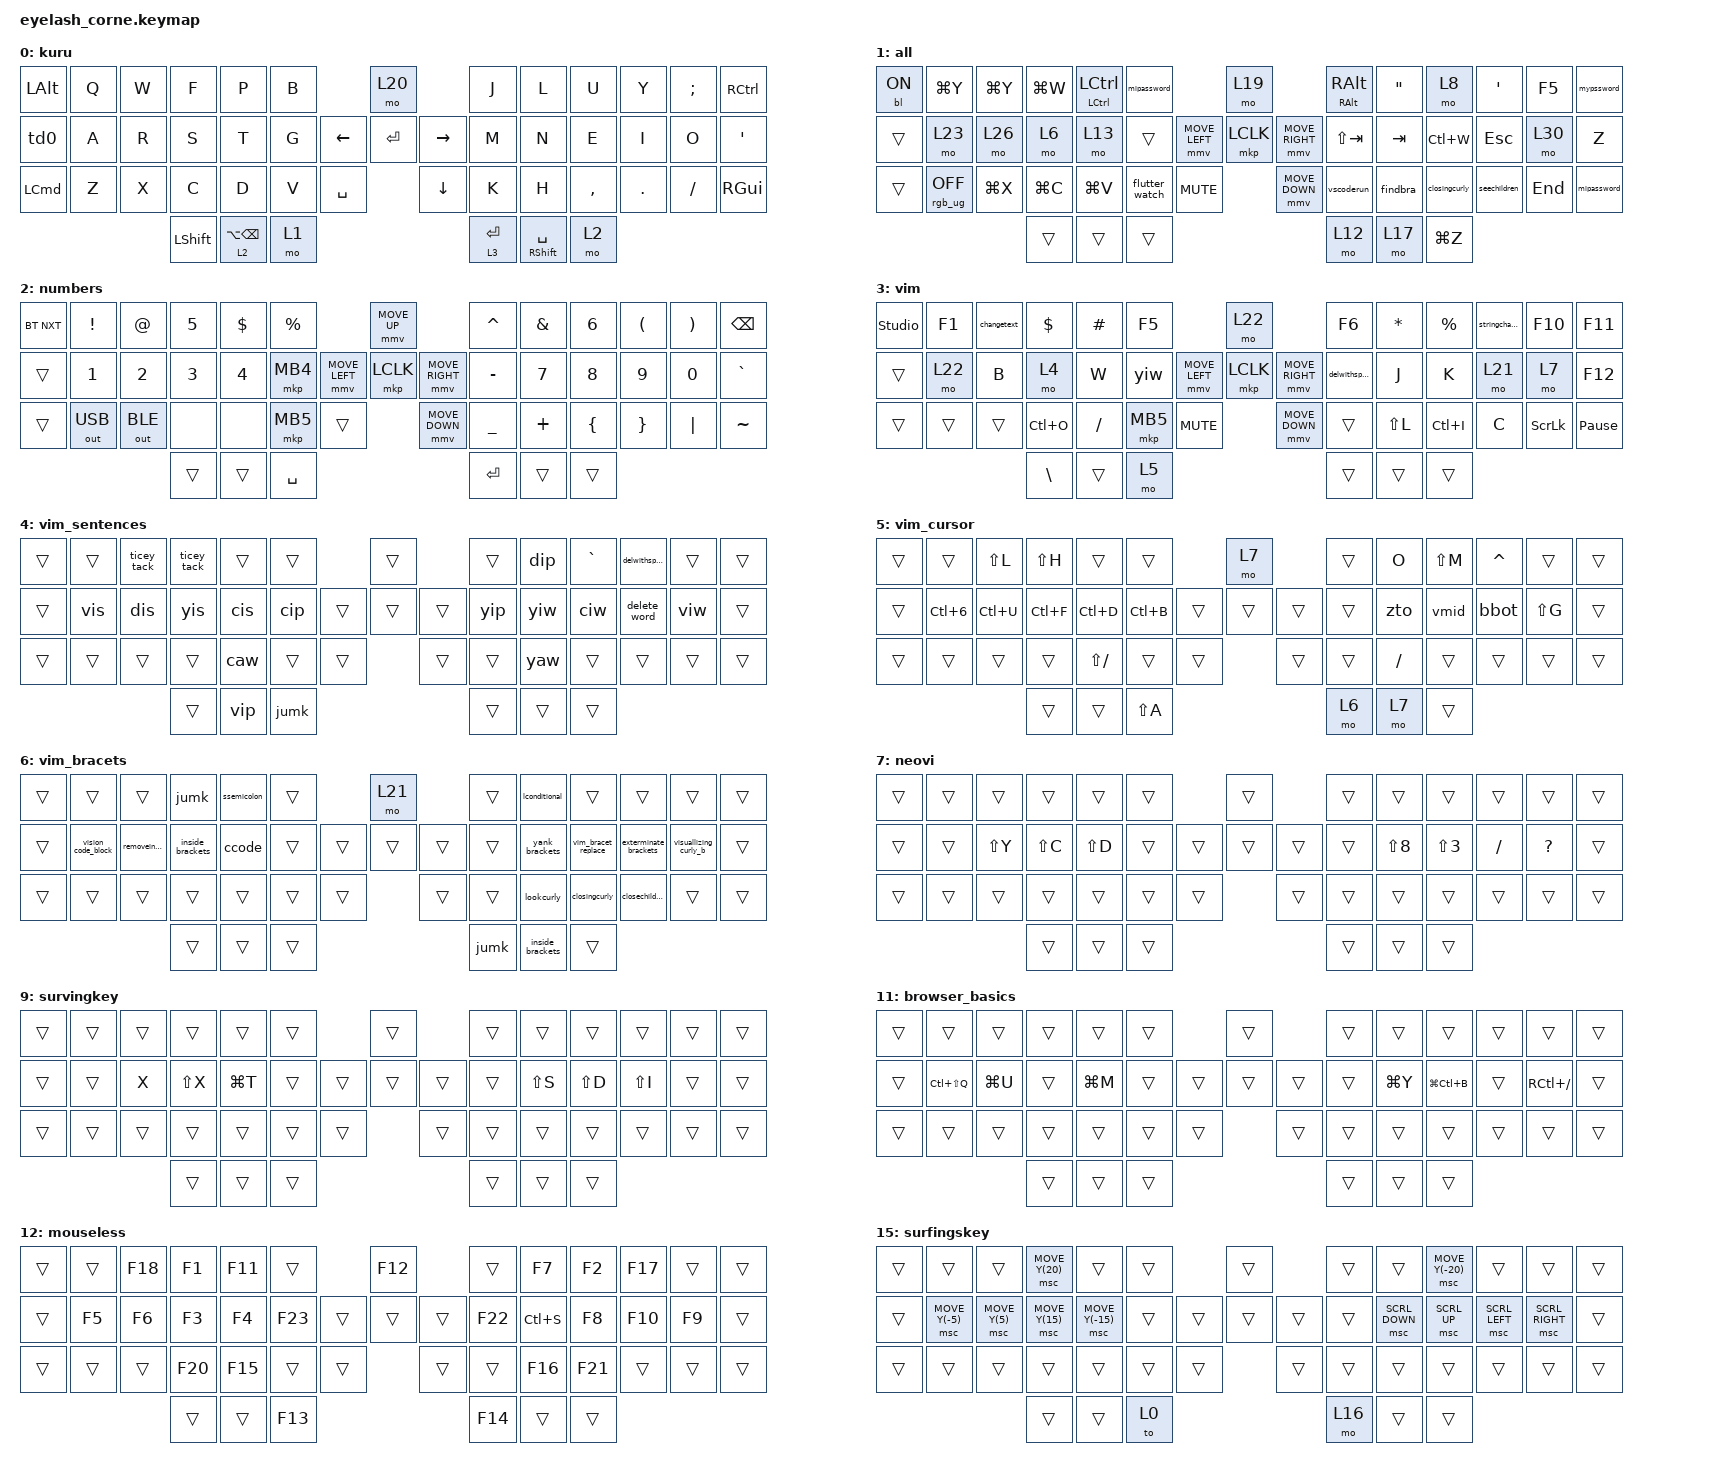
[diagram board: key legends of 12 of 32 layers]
#define ZMK_POINTING_DEFAULT_MOVE_VAL 1200  // 600
#define ZMK_POINTING_DEFAULT_SCRL_VAL 25   // 10

#include <input/processors.dtsi>
#include <zephyr/dt-bindings/input/input-event-codes.h>
#include <behaviors.dtsi>
#include <dt-bindings/zmk/backlight.h>
#include <dt-bindings/zmk/bt.h>
#include <dt-bindings/zmk/keys.h>
#include <dt-bindings/zmk/outputs.h>
#include <dt-bindings/zmk/pointing.h>
#include <dt-bindings/zmk/rgb.h>

&mmv_input_listener { input-processors = <&zip_xy_scaler 2 1>; };

&msc_input_listener { input-processors = <&zip_scroll_scaler 2 1>; };

&msc {
    acceleration-exponent = <1>;      // 0
    time-to-max-speed-ms = <100>;       // 300
    delay-ms = <0>;                   // 0
};

&mmv {
    time-to-max-speed-ms = <500>;
    acceleration-exponent = <1>;
    trigger-period-ms = <16>;
};

&soft_off { hold-time-ms = <2000>; };

/ {
    behaviors {
        td0: td0 {
            compatible = "zmk,behavior-tap-dance";
            display-name = "Shift/Caps Lock Tap Dance";
            #binding-cells = <0>;
            bindings = <&kp LEFT_SHIFT>, <&kp CAPS>;
        };

        new_behavior: new_behavior {
            compatible = "zmk,behavior-hold-tap";
            label = "NEW_BEHAVIOR";
            bindings = <&kp>, <&kp>;

            #binding-cells = <2>;
            flavor = "tap-preferred";
            tapping-term-ms = <230>;
            quick-tap-ms = <230>;
            require-prior-idle-ms = <125>;
        };

        new_behaviorr: new_behaviorr {
            compatible = "zmk,behavior-hold-tap";
            label = "NEW_BEHAVIORR";
            bindings = <&mo>, <&kp>;

            #binding-cells = <2>;
            tapping-term-ms = <230>;
            flavor = "tap-preferred";
            quick-tap-ms = <230>;
            require-prior-idle-ms = <125>;
        };
    };

    rgb_encoder: rgb_encoder {
        compatible = "zmk,behavior-sensor-rotate";
        #sensor-binding-cells = <0>;
        bindings = <&rgb_ug RGB_BRI>, <&rgb_ug RGB_BRD>;
    };

    scroll_encoder: scroll_encoder {
        compatible = "zmk,behavior-sensor-rotate";
        #sensor-binding-cells = <0>;
        bindings = <&msc SCRL_DOWN>, <&msc SCRL_UP>;

        tap-ms = <100>;
    };

    combos {
        compatible = "zmk,combos";

        softoff {
            bindings = <&soft_off>;
            key-positions = <1 15 29>;
        };

        newshitf {
            bindings = <&kp RIGHT_SHIFT>;
            key-positions = <44 46>;
        };
    };

    macros {
        ciw: ciw {
            compatible = "zmk,behavior-macro";
            #binding-cells = <0>;
            bindings = <&kp C &kp I &kp W>;
            label = "CIW";
        };

        viw: viw {
            compatible = "zmk,behavior-macro";
            #binding-cells = <0>;
            bindings = <&kp V &kp I &kp W>;
            label = "VIW";
        };

        yiw: yiw {
            compatible = "zmk,behavior-macro";
            #binding-cells = <0>;
            bindings = <&kp Y &kp I &kp W>;
            label = "YIW";
        };

        ten: ten {
            compatible = "zmk,behavior-macro";
            #binding-cells = <0>;
            bindings = <&kp NUMBER_1 &kp N0>;
            label = "TEN";
        };

        delete_word: delete_word {
            compatible = "zmk,behavior-macro";
            #binding-cells = <0>;
            bindings = <&kp D &kp I &kp W>;
            label = "DELETE_WORD";
        };

        replace_word: visual_w {
            compatible = "zmk,behavior-macro";
            #binding-cells = <0>;
            bindings = <&kp C &kp I &kp LS(W)>;
            label = "VISUAL_W";
        };

        remove_o: remove_o {
            compatible = "zmk,behavior-macro";
            #binding-cells = <0>;
            bindings = <&kp D &kp I &kp LS(W)>;
            label = "REMOVE_O";
        };

        vim_bracet_replace: vim_bracet_replace {
            compatible = "zmk,behavior-macro";
            #binding-cells = <0>;
            bindings = <&kp C &kp I &kp B>;
            label = "VIM_BRACET_REPLACE";
        };

        inside_brackets: inside_brackets {
            compatible = "zmk,behavior-macro";
            #binding-cells = <0>;
            bindings = <&kp C &kp I &kp LS(B)>;
            label = "INSIDE_BRACKETS";
        };

        ccode: erase_in_bracketss {
            compatible = "zmk,behavior-macro";
            #binding-cells = <0>;
            bindings = <&kp Y &kp I &kp B>;
            label = "ERASE_IN_BRACKETSS";
        };

        yank_brackets: yank_brackets {
            compatible = "zmk,behavior-macro";
            #binding-cells = <0>;
            bindings = <&kp Y &kp I &kp LS(B)>;
            label = "YANK_BRACKETS";
        };

        vision_code_block: vision_code_block {
            compatible = "zmk,behavior-macro";
            #binding-cells = <0>;
            bindings = <&kp V &kp I &kp B>;
            label = "VISION_CODE_BLOCK";
        };

        visuallizing_curly_b: visuallizing_curly_brackets {
            compatible = "zmk,behavior-macro";
            #binding-cells = <0>;
            bindings = <&kp V &kp I &kp LS(B)>;
            label = "VISUALLIZING_CURLY_BRACKETS";
        };

        ticey_tack: ticey_tack {
            compatible = "zmk,behavior-macro";
            #binding-cells = <0>;
            bindings = <&kp GRAVE &kp GRAVE>;
            label = "TICEY_TACK";
        };

        zto: zto {
            compatible = "zmk,behavior-macro";
            #binding-cells = <0>;
            bindings = <&kp Z &kp T>;
            label = "ZTO";
        };

        vmid: vmid {
            compatible = "zmk,behavior-macro";
            #binding-cells = <0>;
            bindings = <&kp Z &kp Z>;
            label = "VMID";
        };

        bbot: bbot {
            compatible = "zmk,behavior-macro";
            #binding-cells = <0>;
            bindings = <&kp Z &kp B>;
            label = "BBOT";
        };

        cip: cip {
            compatible = "zmk,behavior-macro";
            #binding-cells = <0>;
            bindings = <&kp C &kp I &kp P>;
            label = "CIP";
        };

        vip: vip {
            compatible = "zmk,behavior-macro";
            #binding-cells = <0>;
            bindings = <&kp V &kp I &kp P>;
            label = "VIP";
        };

        yip: yip {
            compatible = "zmk,behavior-macro";
            #binding-cells = <0>;
            bindings = <&kp Y &kp I &kp P>;
            label = "YIP";
        };

        dip: dip {
            compatible = "zmk,behavior-macro";
            #binding-cells = <0>;
            bindings = <&kp D &kp I &kp P>;
            label = "DIP";
        };

        cis: cis {
            compatible = "zmk,behavior-macro";
            #binding-cells = <0>;
            bindings = <&kp C &kp I &kp S>;
            label = "CIS";
        };

        vis: vis {
            compatible = "zmk,behavior-macro";
            #binding-cells = <0>;
            bindings = <&kp V &kp I &kp S>;
            label = "VIS";
        };

        yis: yis {
            compatible = "zmk,behavior-macro";
            #binding-cells = <0>;
            bindings = <&kp Y &kp I &kp S>;
            label = "YIS";
        };

        dis: dis {
            compatible = "zmk,behavior-macro";
            #binding-cells = <0>;
            bindings = <&kp D &kp I &kp S>;
            label = "DIS";
        };

        caw: caw {
            compatible = "zmk,behavior-macro";
            #binding-cells = <0>;
            bindings = <&kp C &kp A &kp W>;
            label = "CAW";
        };

        yaw: yaw {
            compatible = "zmk,behavior-macro";
            #binding-cells = <0>;
            bindings = <&kp Y &kp A &kp W>;
            label = "YAW";
        };

        endofword: endofword {
            compatible = "zmk,behavior-macro";
            #binding-cells = <0>;
            bindings = <&kp G &kp E>;
            label = "ENDOFWORD";
        };

        jumk: jumk {
            compatible = "zmk,behavior-macro";
            #binding-cells = <0>;
            bindings = <&kp GRAVE &kp N>;
            label = "JUMK";
        };

        splitV: splitV {
            compatible = "zmk,behavior-macro";
            #binding-cells = <0>;
            bindings = <&kp SPACE &kp S &kp V>;
            label = "SPLITV";
        };

        horsplit: horsplit {
            compatible = "zmk,behavior-macro";
            #binding-cells = <0>;
            bindings = <&kp SPACE &kp S &kp H>;
            label = "HORSPLIT";
        };

        closesplit: closesplit {
            compatible = "zmk,behavior-macro";
            #binding-cells = <0>;
            bindings = <&kp SPACE &kp S &kp X>;
            label = "CLOSESPLIT";
        };

        changetext: changetext {
            compatible = "zmk,behavior-macro";
            #binding-cells = <0>;
            bindings = <&kp C &kp I &kp DOUBLE_QUOTES>;
            label = "CHANGETEXT";
        };

        stringchange: stringchange {
            compatible = "zmk,behavior-macro";
            #binding-cells = <0>;
            bindings = <&kp C &kp I &kp SINGLE_QUOTE>;
            label = "STRINGCHANGE";
        };

        fuzzy: fuzzy {
            compatible = "zmk,behavior-macro";
            #binding-cells = <0>;
            bindings = <&kp F &kp Z &kp F>;
            label = "FUZZY";
        };

        aroundpara: aroundpara {
            compatible = "zmk,behavior-macro";
            #binding-cells = <0>;
            bindings = <&kp D &kp A &kp P>;
            label = "AROUNDPARA";
        };

        gospace: gospace {
            compatible = "zmk,behavior-macro";
            #binding-cells = <0>;
            bindings = <&kp F &kp SPACE>;
            label = "GOSPACE";
        };

        findbra: findbra {
            compatible = "zmk,behavior-macro";
            #binding-cells = <0>;
            bindings = <&kp F &kp LS(NUMBER_9)>;
            label = "FINDBRA";
        };

        lookcurly: lookcurly {
            compatible = "zmk,behavior-macro";
            #binding-cells = <0>;
            bindings = <&kp F &kp LEFT_BRACE>;
            label = "LOOKCURLY";
        };

        ssemicolon: ssemicolon {
            compatible = "zmk,behavior-macro";
            #binding-cells = <0>;
            bindings = <&kp F &kp SEMICOLON>;
            label = "SSEMICOLON";
        };

        closingcurly: closingcurly {
            compatible = "zmk,behavior-macro";
            #binding-cells = <0>;
            bindings = <&kp F &kp LS(N0)>;
            label = "CLOSINGCURLY";
        };

        lockedbra: lockedbra {
            compatible = "zmk,behavior-macro";
            #binding-cells = <0>;
            bindings = <&kp F &kp RIGHT_BRACE>;
            label = "LOCKEDBRA";
        };

        seechildren: seechildren {
            compatible = "zmk,behavior-macro";
            #binding-cells = <0>;
            bindings = <&kp F &kp LEFT_BRACKET>;
            label = "SEECHILDREN";
        };

        closechildren: closechildren {
            compatible = "zmk,behavior-macro";
            #binding-cells = <0>;
            bindings = <&kp F &kp RIGHT_BRACKET>;
            label = "CLOSECHILDREN";
        };

        lconditional: lconditional {
            compatible = "zmk,behavior-macro";
            #binding-cells = <0>;
            bindings = <&kp F &kp LS(SEMI)>;
            label = "LCONDITIONAL";
        };

        mask: mask {
            compatible = "zmk,behavior-macro";
            #binding-cells = <0>;
            bindings = <&kp CARET &kp LS(M)>;
            label = "MASK";
        };

        Component: Component {
            compatible = "zmk,behavior-macro";
            #binding-cells = <0>;
            bindings = <&kp CARET &kp LA(LG(K))>;
            label = "COMPONENT";
        };

        mipassword: mipassword {
            compatible = "zmk,behavior-macro";
            #binding-cells = <0>;
            bindings = <&kp M &kp I &kp G &kp B &kp Y &kp T &kp E &kp DOLLAR &kp PERCENT>;
            label = "MIPASSWORD";
        };

        muxprev: muxprev {
            compatible = "zmk,behavior-macro";
            #binding-cells = <0>;
            bindings = <&kp LC(N) &kp LC(P)>;
            label = "MUXPREV";
        };

        delwithspacedaw: delwithspacedaw {
            compatible = "zmk,behavior-macro";
            #binding-cells = <0>;
            bindings = <&kp D &kp W>;
            label = "DELWITHSPACEDAW";
        };

        winsert: winsert {
            compatible = "zmk,behavior-macro";
            #binding-cells = <0>;
            bindings = <&kp LC(O) &kp W>;
            label = "WINSERT";
        };

        begininsertmode: begininsertmode {
            compatible = "zmk,behavior-macro";
            #binding-cells = <0>;
            bindings = <&kp LC(O) &kp B>;
            label = "BEGININSERTMODE";
        };

        endinertm: endinertm {
            compatible = "zmk,behavior-macro";
            #binding-cells = <0>;
            bindings = <&kp LC(O) &kp RIGHT_ARROW &kp E>;
            label = "ENDINERTM";
        };

        var: var {
            compatible = "zmk,behavior-macro";
            #binding-cells = <0>;
            bindings = <&kp DOLLAR &kp V &kp A &kp R>;
            label = "VAR";
        };

        eloquentchain: eloquentchain {
            compatible = "zmk,behavior-macro";
            #binding-cells = <0>;
            bindings = <&kp MINUS &kp GREATER_THAN>;
            label = "ELOQUENTCHAIN";
        };

        phpopening: phpopening {
            compatible = "zmk,behavior-macro";
            #binding-cells = <0>;
            bindings = <&kp LESS_THAN &kp QUESTION &kp P &kp H &kp P &kp QUESTION &kp GREATER_THAN>;
            label = "PHPOPENING";
        };

        mypssword: mypssword {
            compatible = "zmk,behavior-macro";
            #binding-cells = <0>;
            bindings = <&kp SINGLE_QUOTE &kp PERIOD>;
            label = "MYPSSWORD";
        };

        lastinertlo: lastinertlo {
            compatible = "zmk,behavior-macro";
            #binding-cells = <0>;
            bindings = <&kp SINGLE_QUOTE &kp CARET>;
            label = "LASTINERTLO";
        };

        lastvimchange: lastvimchange {
            compatible = "zmk,behavior-macro";
            #binding-cells = <0>;
            bindings = <&kp SINGLE_QUOTE &kp LEFT_BRACKET>;
            label = "LASTVIMCHANGE";
        };

        firstvimchange: firstvimchange {
            compatible = "zmk,behavior-macro";
            #binding-cells = <0>;
            bindings = <&kp SINGLE_QUOTE &kp RIGHT_BRACKET>;
            label = "FIRSTVIMCHANGE";
        };

        nexterror: nexterror {
            compatible = "zmk,behavior-macro";
            #binding-cells = <0>;
            bindings = <&kp RIGHT_BRACKET &kp E>;
            label = "NEXTERROR";
        };

        nextdiagnostic: nextdiagnostic {
            compatible = "zmk,behavior-macro";
            #binding-cells = <0>;
            bindings = <&kp RIGHT_BRACKET &kp D>;
            label = "NEXTDIAGNOSTIC";
        };

        previousdiagnostic: previousdiagnostic {
            compatible = "zmk,behavior-macro";
            #binding-cells = <0>;
            bindings = <&kp LEFT_BRACKET &kp D>;
            label = "PREVIOUSDIAGNOSTIC";
        };

        previouserror: previouserror {
            compatible = "zmk,behavior-macro";
            #binding-cells = <0>;
            bindings = <&kp LEFT_BRACKET &kp E>;
            label = "PREVIOUSERROR";
        };

        removeinsidebraa: removeinsidebraa {
            compatible = "zmk,behavior-macro";
            #binding-cells = <0>;
            bindings = <&kp D &kp I &kp B>;
            label = "REMOVEINSIDEBRAA";
        };

        vision_curly_brackets: vision_curly_brackets {
            compatible = "zmk,behavior-macro";
            #binding-cells = <0>;
            bindings = <&kp V &kp I &kp LS(B)>;
            label = "VISION_CURLY_BRACKETS";
        };

        exterminate_brackets: exterminate_brackets {
            compatible = "zmk,behavior-macro";
            #binding-cells = <0>;
            bindings = <&kp D &kp I &kp LS(B)>;
            label = "EXTERMINATE_BRACKETS";
        };

        vscoderun: vscoderun {
            compatible = "zmk,behavior-macro";
            #binding-cells = <0>;
            bindings = <&kp CARET &kp F5>;
            label = "VSCODERUN";
        };

        flutter_watch: flutter_watch {
            compatible = "zmk,behavior-macro";
            #binding-cells = <0>;
            bindings = <&none &kp F &kp L &kp U &kp T &kp T &kp E &kp R &kp MINUS &kp W &kp A &kp T &kp C &kp H>;
            label = "FLUTTER_WATCH";
        };

        browser_surfing: browser_surfing {
            compatible = "zmk,behavior-macro";
            #binding-cells = <0>;
            bindings = <&none &kp H &kp T &kp T &kp P &kp S &kp COLON &kp FSLH &kp FSLH &kp D &kp R &kp I &kp V &kp E &kp DOT &kp G &kp O &kp O &kp G &kp L &kp E &kp DOT &kp C &kp O &kp M &kp FSLH &kp F &kp I &kp L &kp E &kp FSLH &kp D &kp FSLH &kp N1 &kp LS(Y) &kp T &kp LS(Q) &kp MINUS &kp LS(N) &kp E &kp U &kp T &kp M &kp T &kp LS(R) &kp O &kp N &kp N &kp H &kp G &kp LS(S) &kp B &kp LS(K) &kp N5 &kp LS(H) &kp LS(E) &kp UNDER &kp N0 &kp G &kp Y &kp X &kp LS(Z) &kp T &kp O &kp LS(G) &kp LS(U) &kp FSLH &kp V &kp I &kp E &kp W &kp QMARK &kp U &kp S &kp P &kp EQUAL &kp S &kp H &kp A &kp R &kp I &kp N &kp G>;
            label = "BROWSER_SURFING";
        };
    };

    keymap {
        compatible = "zmk,keymap";

        default_layer {
            display-name = "kuru";
            bindings = <
&kp LEFT_ALT      &kp Q  &kp W  &kp F           &kp P                           &kp B                         &mo 20                &kp J        &kp L                            &kp U      &kp Y    &kp SEMICOLON  &kp RIGHT_CONTROL
&td0              &kp A  &kp R  &kp S           &kp T                           &kp G               &kp LEFT  &kp ENTER  &kp RIGHT  &kp M        &kp N                            &kp E      &kp I    &kp O          &kp SQT
&kp LEFT_COMMAND  &kp Z  &kp X  &kp C           &kp D                           &kp V  &kp SPACE              &kp DOWN              &kp K        &kp H                            &kp COMMA  &kp DOT  &kp FSLH       &kp RIGHT_GUI
                                &kp LEFT_SHIFT  &new_behaviorr 2 LA(BACKSPACE)  &mo 1                                               &lt 3 ENTER  &new_behavior RIGHT_SHIFT SPACE  &mo 2
            >;

            sensor-bindings = <&inc_dec_kp C_VOLUME_UP C_VOLUME_DOWN>;
        };

        all_layer {
            display-name = "all";
            bindings = <
&bl BL_ON  &kp LG(Y)        &kp LG(Y)  &kp LG(W)  &mt LCTRL LCTRL  &mipassword                                   &mo 19                           &mt RIGHT_ALT RIGHT_ALT  &kp DOUBLE_QUOTES  &mo 8          &kp SINGLE_QUOTE  &kp F5   &mypssword
&trans     &mo 23           &mo 26     &mo 6      &mo 13           &trans                        &mmv MOVE_LEFT  &mkp LCLK       &mmv MOVE_RIGHT  &kp LS(TAB)              &kp TAB            &kp LC(W)      &kp ESCAPE        &mo 30   &kp Z
&trans     &rgb_ug RGB_OFF  &kp LG(X)  &kp LG(C)  &kp LG(V)        &flutter_watch  &kp C_MUTE                    &mmv MOVE_DOWN                   &vscoderun               &findbra           &closingcurly  &seechildren      &kp END  &mipassword
                                       &trans     &trans           &trans                                                                         &mo 12                   &mo 17             &kp LG(Z)
            >;

            sensor-bindings = <&scroll_encoder>;
        };

        numbers_layer {
            display-name = "numbers";
            bindings = <
&bt BT_NXT  &kp EXCL      &kp AT        &kp N5        &kp DLLR      &kp PRCNT                            &mmv MOVE_UP                     &kp CARET  &kp AMPS  &kp NUMBER_6  &kp LPAR  &kp RPAR  &kp BSPC
&trans      &kp NUMBER_1  &kp NUMBER_2  &kp NUMBER_3  &kp NUMBER_4  &mkp MB4             &mmv MOVE_LEFT  &mkp LCLK       &mmv MOVE_RIGHT  &kp MINUS  &kp N7    &kp N8        &kp N9    &kp N0    &kp GRAVE
&trans      &out OUT_USB  &out OUT_BLE  &none         &none         &mkp MB5   &trans                    &mmv MOVE_DOWN                   &kp UNDER  &kp PLUS  &kp LBRC      &kp RBRC  &kp PIPE  &kp TILDE
                                        &trans        &trans        &kp SPACE                                                             &kp RET    &trans    &trans
            >;

            sensor-bindings = <&scroll_encoder>;
        };

        vim_layer {
            display-name = "vim";
            bindings = <
&studio_unlock  &kp F1  &changetext  &kp DOLLAR     &kp HASH   &kp F5                                  &mo 22                           &kp F6            &kp ASTERISK  &kp PERCENT  &stringchange  &kp F10         &kp F11
&trans          &mo 22  &kp B        &mo 4          &kp W      &yiw                    &mmv MOVE_LEFT  &mkp LCLK       &mmv MOVE_RIGHT  &delwithspacedaw  &kp J         &kp K        &mo 21         &mo 7           &kp F12
&trans          &trans  &trans       &kp LC(O)      &kp SLASH  &mkp MB5  &kp C_MUTE                    &mmv MOVE_DOWN                   &trans            &kp LS(L)     &kp LC(I)    &kp C          &kp SCROLLLOCK  &kp PAUSE_BREAK
                                     &kp BACKSLASH  &trans     &mo 5                                                                    &trans            &trans        &trans
            >;

            sensor-bindings = <&scroll_encoder>;
        };

        vim_sentences {
            bindings = <
&trans  &trans  &ticey_tack  &ticey_tack  &trans  &trans                    &trans          &trans  &dip    &kp GRAVE  &delwithspacedaw  &trans  &trans
&trans  &vis    &dis         &yis         &cis    &cip              &trans  &trans  &trans  &yip    &yiw    &ciw       &delete_word      &viw    &trans
&trans  &trans  &trans       &trans       &caw    &trans  &trans            &trans          &trans  &yaw    &trans     &trans            &trans  &trans
                             &trans       &vip    &jumk                                     &trans  &trans  &trans
            >;
        };

        vim_cursor {
            bindings = <
&trans  &trans            &kp LS(L)  &kp LS(H)  &trans         &trans                       &mo 7           &trans  &kp O      &kp LS(M)  &kp CARET  &trans     &trans
&trans  &kp LC(NUMBER_6)  &kp LC(U)  &kp LC(F)  &kp LC(D)      &kp LC(B)            &trans  &trans  &trans  &trans  &zto       &vmid      &bbot      &kp LS(G)  &trans
&trans  &trans            &trans     &trans     &kp LS(SLASH)  &trans     &trans            &trans          &trans  &kp SLASH  &trans     &trans     &trans     &trans
                                     &trans     &trans         &kp LS(A)                                    &mo 6   &mo 7      &trans
            >;
        };

        vim_bracets {
            bindings = <
&trans  &trans              &trans             &jumk             &ssemicolon  &trans                    &mo 21          &trans  &lconditional     &trans               &trans                 &trans                 &trans
&trans  &vision_code_block  &removeinsidebraa  &inside_brackets  &ccode       &trans            &trans  &trans  &trans  &trans  &yank_brackets    &vim_bracet_replace  &exterminate_brackets  &visuallizing_curly_b  &trans
&trans  &trans              &trans             &trans            &trans       &trans  &trans            &trans          &trans  &lookcurly        &closingcurly        &closechildren         &trans                 &trans
                                               &trans            &trans       &trans                                    &jumk   &inside_brackets  &trans
            >;
        };

        neovi {
            bindings = <
&trans  &trans  &trans     &trans     &trans     &trans                    &trans          &trans  &trans      &trans            &trans     &trans     &trans
&trans  &trans  &kp LS(Y)  &kp LS(C)  &kp LS(D)  &trans            &trans  &trans  &trans  &trans  &kp LS(N8)  &kp LS(NUMBER_3)  &kp SLASH  &kp QMARK  &trans
&trans  &trans  &trans     &trans     &trans     &trans  &trans            &trans          &trans  &trans      &trans            &trans     &trans     &trans
                           &trans     &trans     &trans                                    &trans  &trans      &trans
            >;
        };

        browser {
            bindings = <
&trans  &trans             &trans  &kp LG(W)          &trans             &trans                               &mo 12          &trans  &trans  &trans  &kp LG(T)  &trans  &trans
&trans  &kp LC(LA(LS(F)))  &trans  &kp LC(LA(LS(B)))  &kp LC(LA(LS(P)))  &kp LS(LA(LC(W)))            &trans  &trans  &trans  &trans  &mo 15  &trans  &mo 16     &mo 11  &trans
&trans  &trans             &trans  &trans             &trans             &trans             &trans            &trans          &trans  &trans  &trans  &trans     &trans  &trans
                                   &trans             &trans             &trans                                               &mo 9   &trans  &trans
            >;
        };

        survingkey {
            bindings = <
&trans  &trans  &trans  &trans     &trans     &trans                    &trans          &trans  &trans     &trans     &trans     &trans  &trans
&trans  &trans  &kp X   &kp LS(X)  &kp LG(T)  &trans            &trans  &trans  &trans  &trans  &kp LS(S)  &kp LS(D)  &kp LS(I)  &trans  &trans
&trans  &trans  &trans  &trans     &trans     &trans  &trans            &trans          &trans  &trans     &trans     &trans     &trans  &trans
                        &trans     &trans     &trans                                    &trans  &trans     &trans
            >;
        };

        browser_shortcuts {
            bindings = <
&trans  &trans  &trans  &trans         &trans        &trans                    &trans          &trans  &trans         &trans     &trans                 &trans                         &trans
&trans  &trans  &trans  &kp LG(MINUS)  &kp LG(PLUS)  &trans            &trans  &trans  &trans  &trans  &kp LG(LS(P))  &kp LC(P)  &kp LC(LG(LA(LS(X))))  &kp LG(LC(LA(LS(SEMICOLON))))  &trans
&trans  &trans  &trans  &trans         &trans        &trans  &trans            &trans          &trans  &trans         &trans     &trans                 &trans                         &trans
                        &trans         &trans        &trans                                    &trans  &trans         &trans
            >;
        };

        browser_basics {
            bindings = <
&trans  &trans         &trans     &trans  &trans     &trans                    &trans          &trans  &trans     &trans         &trans  &trans         &trans
&trans  &kp LC(LS(Q))  &kp LG(U)  &trans  &kp LG(M)  &trans            &trans  &trans  &trans  &trans  &kp LG(Y)  &kp LG(LC(B))  &trans  &kp RC(SLASH)  &trans
&trans  &trans         &trans     &trans  &trans     &trans  &trans            &trans          &trans  &trans     &trans         &trans  &trans         &trans
                                  &trans  &trans     &trans                                    &trans  &trans     &trans
            >;
        };

        mouseless {
            bindings = <
&trans  &trans  &kp F18  &kp F1   &kp F11  &trans                     &kp F12          &trans   &kp F7     &kp F2   &kp F17  &trans  &trans
&trans  &kp F5  &kp F6   &kp F3   &kp F4   &kp F23            &trans  &trans   &trans  &kp F22  &kp LC(S)  &kp F8   &kp F10  &kp F9  &trans
&trans  &trans  &trans   &kp F20  &kp F15  &trans   &trans            &trans           &trans   &kp F16    &kp F21  &trans   &trans  &trans
                         &trans   &trans   &kp F13                                     &kp F14  &trans     &trans
            >;
        };

        raycast {
            bindings = <
&trans  &trans              &kp LS(LG(PERIOD))  &kp LS(LA(LC(G)))  &trans  &trans                    &mo 15          &kp LS(LG(C))          &kp LG(Y)          &kp LS(LA(LG(PERIOD)))  &kp LG(PERIOD)         &trans                 &trans
&trans  &kp LG(LS(PERIOD))  &mo 14              &mo 17             &trans  &trans            &trans  &trans  &trans  &kp LG(LA(LC(LS(Y))))  &kp LS(LC(COMMA))  &kp LG(LA(LC(LS(U))))   &kp LG(LA(LC(LS(I))))  &kp LC(LA(LS(X)))      &trans
&trans  &trans              &kp LC(X)           &kp LS(LG(R))      &trans  &trans  &trans            &trans          &kp LG(I)              &kp LG(K)          &kp LG(O)               &kp LG(ENTER)          &kp LS(LC(LA(SLASH)))  &trans
                                                &trans             &trans  &mo 19                                    &kp LS(LA(Y))          &kp LS(LG(L))      &kp LC(LS(Q))
            >;
        };

        raycast_apps {
            bindings = <
&trans  &trans  &trans  &kp LS(LG(Z))  &trans  &trans                    &trans          &trans         &trans             &kp LG(LA(LC(LS(D))))  &trans                 &trans                 &trans
&trans  &trans  &trans  &trans         &trans  &trans            &trans  &trans  &trans  &trans         &kp LA(LS(LG(G)))  &kp LG(K)              &kp LG(LC(LA(LS(L))))  &kp LG(LC(LA(LS(K))))  &trans
&trans  &trans  &trans  &trans         &trans  &trans  &trans            &trans          &trans         &trans             &trans                 &trans                 &trans                 &trans
                        &trans         &trans  &mo 15                                    &kp LC(LS(Q))  &trans             &trans
            >;
        };

        surfingskey {
            bindings = <
&trans  &trans           &trans          &msc MOVE_Y(20)  &trans            &trans                    &trans          &trans  &trans          &msc MOVE_Y(-20)  &trans          &trans           &trans
&trans  &msc MOVE_Y(-5)  &msc MOVE_Y(5)  &msc MOVE_Y(15)  &msc MOVE_Y(-15)  &trans            &trans  &trans  &trans  &trans  &msc SCRL_DOWN  &msc SCRL_UP      &msc SCRL_LEFT  &msc SCRL_RIGHT  &trans
&trans  &trans           &trans          &trans           &trans            &trans  &trans            &trans          &trans  &trans          &trans            &trans          &trans           &trans
                                         &trans           &trans            &to 0                                     &mo 16  &trans          &trans
            >;
        };

        surf {
            bindings = <
&trans  &trans  &trans  &trans     &trans     &trans                    &trans          &trans  &trans          &none         &trans          &trans           &trans
&trans  &trans  &trans  &mkp LCLK  &mkp RCLK  &trans            &trans  &trans  &trans  &trans  &mmv MOVE_DOWN  &mmv MOVE_UP  &mmv MOVE_LEFT  &mmv MOVE_RIGHT  &trans
&trans  &trans  &trans  &trans     &trans     &trans  &trans            &trans          &trans  &trans          &trans        &trans          &trans           &trans
                        &trans     &trans     &to 0                                     &to 15  &trans          &trans
            >;
        };

        tmux_ghostty {
            bindings = <
&trans  &trans           &trans          &trans        &trans        &trans                    &trans          &trans  &trans         &kp LS(A)  &trans                 &trans                    &trans
&trans  &firstvimchange  &lastvimchange  &lastinertlo  &lastinertlo  &trans            &trans  &trans  &trans  &trans  &kp LC(LS(R))  &kp LC(N)  &kp LS(LA(LC(LG(Z))))  &kp LG(LA(LC(LS(SEMI))))  &trans
&trans  &trans           &trans          &trans        &trans        &trans  &trans            &trans          &trans  &trans         &trans     &trans                 &trans                    &trans
                                         &trans        &trans        &trans                                    &trans  &trans         &trans
            >;
        };

        figma {
            bindings = <
&trans  &trans         &mt LS(LG(C)) LG(LS(V))  &mt LA(LG(C)) LG(C)  &mt LA(LG(V)) LG(V)  &trans                         &trans          &trans  &trans  &trans  &trans  &trans  &trans
&to 0   &kp BACKSPACE  &kp LG(Z)                &kp LEFT_SHIFT       &mt LS(LA(A)) LS(A)  &mt I LS(X)            &trans  &trans  &trans  &trans  &trans  &trans  &trans  &trans  &trans
&trans  &trans         &trans                   &mt LS(SPACE) RG(K)  &mt K V              &trans       &trans            &trans          &trans  &trans  &trans  &trans  &trans  &trans
                                                &trans               &mo 20               &mo 19                                         &trans  &trans  &trans
            >;
        };

        symbols_layer {
            bindings = <
&rgb_ug RGB_ON  &trans     &rgb_ug RGB_COLOR_HSB(0,100,45)    &kp UNDER   &rgb_ug RGB_EFF                   &trans                    &trans          &trans  &rgb_ug RGB_EFR  &kp MINUS  &rgb_ug RGB_COLOR_HSB(124,100,48)  &trans         &rgb_ug RGB_OFF
&trans          &kp CARET  &kp SLASH                          &kp DOLLAR  &kp PERCENT                       &trans            &trans  &trans  &trans  &trans  &kp HASH         &kp AT     &kp DOLLAR                         &kp BACKSLASH  &trans
&trans          &trans     &rgb_ug RGB_COLOR_HSB(221,100,50)  &trans      &rgb_ug RGB_COLOR_HSB(66,100,49)  &trans  &trans            &trans          &trans  &trans           &trans     &rgb_ug RGB_COLOR_HSB(41,100,49)   &trans         &trans
                                                              &trans      &trans                            &trans                                    &trans  &trans           &trans
            >;
        };

        captl {
            bindings = <
&trans     &kp LS(Q)  &kp LS(W)  &kp LS(F)  &kp LS(P)  &kp LS(B)                    &trans          &kp LS(J)  &kp LS(L)  &kp LS(U)      &kp LS(Y)       &kp LS(SEMICOLON)  &trans
&kp LS(Q)  &kp LS(A)  &kp LS(R)  &kp LS(S)  &kp LS(T)  &kp LS(G)            &trans  &trans  &trans  &kp LS(M)  &kp LS(N)  &kp LS(E)      &kp LS(I)       &kp LS(O)          &kp LS(Z)
&trans     &kp LS(Z)  &kp LS(X)  &kp LS(C)  &kp LS(D)  &kp LS(V)  &trans            &trans          &kp LS(K)  &kp LS(H)  &kp LS(COMMA)  &kp LS(PERIOD)  &kp LS(SLASH)      &trans
                                 &trans     &kp LS(Q)  &mo 19                                       &trans     &trans     &trans
            >;
        };

        vimuium {
            bindings = <
&trans  &trans               &trans           &kp Q           &trans             &trans                      &trans          &trans     &trans     &kp LS(NUMBER_2)  &trans       &trans  &trans
&trans  &previousdiagnostic  &nextdiagnostic  &previouserror  &nexterror         &trans              &trans  &trans  &trans  &trans     &kp LC(N)  &kp LC(P)         &aroundpara  &fuzzy  &trans
&trans  &trans               &trans           &trans          &trans             &trans    &trans            &trans          &trans     &trans     &trans            &trans       &trans  &trans
                                              &trans          &kp LG(BACKSPACE)  &muxprev                                    &kp LC(O)  &trans     &trans
            >;
        };

        fucs {
            bindings = <
&trans  &trans  &trans       &trans   &trans     &trans                    &trans          &trans  &trans     &trans     &trans     &trans     &trans
&trans  &trans  &closesplit  &splitV  &horsplit  &trans            &trans  &trans  &trans  &trans  &kp LC(H)  &kp LC(L)  &kp LC(J)  &kp LC(K)  &trans
&trans  &trans  &trans       &trans   &trans     &trans  &trans            &trans          &trans  &trans     &trans     &trans     &trans     &trans
                             &trans   &trans     &trans                                    &trans  &trans     &trans
            >;
        };

        workspaces {
            bindings = <
&trans  &trans  &trans         &kp LG(LA(LS(W)))  &trans             &trans                    &trans          &trans  &trans             &kp LG(LA(LS(U)))  &trans             &trans             &trans
&trans  &trans  &kp LA(LG(E))  &mo 24             &kp LG(LA(LS(B)))  &trans            &trans  &trans  &trans  &trans  &kp LG(LA(LS(S)))  &kp LG(LA(LS(D)))  &kp LG(LA(LS(F)))  &kp LG(LA(LS(G)))  &trans
&trans  &trans  &trans         &trans             &kp LG(LA(LS(Y)))  &trans  &trans            &trans          &trans  &kp LG(LA(LS(A)))  &trans             &trans             &trans             &trans
                               &trans             &trans             &trans                                    &mo 25  &trans             &trans
            >;
        };

        workspace_layouts {
            bindings = <
&trans  &trans         &trans  &trans  &trans             &trans                    &kp LG(LS(MINUS))          &trans             &trans             &trans         &trans         &trans         &trans
&trans  &kp LG(SLASH)  &trans  &trans  &kp LG(PERIOD)     &trans            &trans  &trans             &trans  &trans             &kp LG(LS(H))      &kp LG(LS(J))  &kp LG(LS(K))  &kp LG(LS(L))  &trans
&trans  &trans         &trans  &trans  &kp LG(LS(MINUS))  &trans  &trans            &trans                     &trans             &kp LG(LS(EQUAL))  &trans         &trans         &trans         &trans
                               &trans  &trans             &trans                                               &kp LG(LS(EQUAL))  &trans             &trans
            >;
        };

        wordspace_focus {
            bindings = <
&trans  &trans     &trans  &kp LG(LS(MINUS))  &trans          &trans                    &trans          &trans  &trans         &kp LG(LS(EQUAL))  &trans     &trans     &trans
&trans  &kp LG(B)  &trans  &trans             &kp LG(LS(A))   &trans            &trans  &trans  &trans  &trans  &kp LG(H)      &kp LG(L)          &kp LG(J)  &kp LG(K)  &trans
&trans  &trans     &trans  &trans             &kp LG(PERIOD)  &trans  &trans            &trans          &trans  &kp LG(SLASH)  &trans             &trans     &trans     &trans
                           &trans             &trans          &trans                                    &trans  &trans         &trans
            >;
        };

        arrow_movements {
            bindings = <
&trans  &trans  &trans  &trans  &trans  &trans                     &kp LS(A)          &trans  &trans    &trans        &trans          &trans     &trans
&trans  &mo 28  &trans  &mo 27  &mo 29  &trans             &trans  &trans     &trans  &trans  &kp DOWN  &kp UP_ARROW  &kp LEFT_ARROW  &kp RIGHT  &trans
&trans  &trans  &trans  &trans  &trans  &trans   &trans            &trans             &trans  &trans    &trans        &trans          &trans     &trans
                        &trans  &trans  &tog 16                                       &trans  &trans    &trans
            >;
        };

        best_move {
            bindings = <
&trans  &trans  &trans  &trans  &trans  &trans                    &trans          &trans  &trans              &trans               &trans        &trans            &trans
&trans  &trans  &trans  &trans  &trans  &trans            &trans  &trans  &trans  &trans  &kp LA(LEFT_ARROW)  &kp LA(RIGHT_ARROW)  &kp LA(DOWN)  &kp LA(UP_ARROW)  &trans
&trans  &trans  &trans  &trans  &trans  &trans  &trans            &trans          &trans  &trans              &trans               &trans        &trans            &trans
                        &trans  &trans  &trans                                    &trans  &trans              &trans
            >;
        };

        gar {
            bindings = <
&trans  &trans  &trans  &trans  &trans  &trans                    &trans          &trans  &trans              &trans               &trans              &trans            &trans
&trans  &trans  &trans  &trans  &trans  &trans            &trans  &trans  &trans  &trans  &kp LG(LEFT_ARROW)  &kp LG(RIGHT_ARROW)  &kp LG(DOWN_ARROW)  &kp LG(UP_ARROW)  &trans
&trans  &trans  &trans  &trans  &trans  &trans  &trans            &trans          &trans  &trans              &trans               &trans              &trans            &trans
                        &trans  &trans  &trans                                    &trans  &trans              &trans
            >;
        };

        layer_29 {
            bindings = <
&trans  &trans  &trans  &trans  &trans  &trans                    &trans          &trans  &trans            &trans    &trans      &trans     &trans
&trans  &trans  &trans  &trans  &trans  &trans            &trans  &trans  &trans  &trans  &begininsertmode  &winsert  &endinertm  &kp LC(O)  &trans
&trans  &trans  &trans  &trans  &trans  &trans  &trans            &trans          &trans  &trans            &trans    &trans      &trans     &trans
                        &trans  &trans  &trans                                    &trans  &trans            &trans
            >;
        };

        coding {
            bindings = <
&bt BT_SEL 2    &trans            &trans             &kp UNDER       &trans             &trans                    &trans          &trans  &trans                &kp MINUS              &trans         &trans  &bt BT_SEL 4
&trans          &kp LEFT_BRACKET  &kp RIGHT_BRACKET  &kp LEFT_BRACE  &kp RIGHT_BRACE    &trans            &trans  &trans  &trans  &trans  &kp LEFT_PARENTHESIS  &kp RIGHT_PARENTHESIS  &kp SEMICOLON  &trans  &trans
&bt BT_CLR_ALL  &trans            &trans             &trans          &kp LS(SEMICOLON)  &trans  &trans            &trans          &trans  &kp AT                &trans                 &trans         &trans  &bt BT_SEL 3
                                                     &trans          &trans             &mo 19                                    &mo 31  &trans                &trans
            >;
        };

        programming {
            bindings = <
&trans  &trans    &trans    &trans    &trans     &trans                    &trans          &trans  &trans         &trans        &trans            &trans  &trans
&trans  &kp PIPE  &kp EXCL  &kp PLUS  &kp EQUAL  &trans            &trans  &trans  &trans  &trans  &kp LESS_THAN  &kp QUESTION  &kp GREATER_THAN  &trans  &trans
&trans  &trans    &trans    &trans    &trans     &trans  &trans            &trans          &trans  &trans         &trans        &trans            &trans  &trans
                            &trans    &trans     &trans                                    &trans  &trans         &trans
            >;
        };
    };
};
